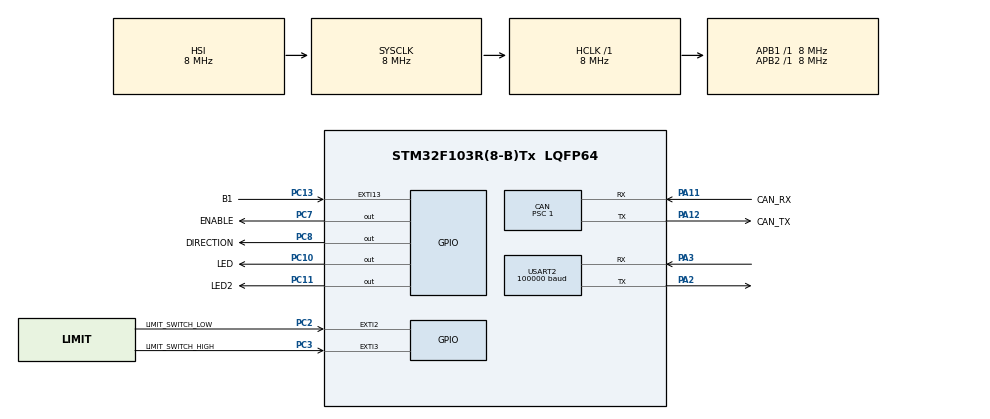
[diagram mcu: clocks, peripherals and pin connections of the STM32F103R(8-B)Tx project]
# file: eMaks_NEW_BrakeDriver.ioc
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CAN.BS1=CAN_BS1_4TQ
CAN.BS2=CAN_BS2_3TQ
CAN.CalculateTimeBit=1000
CAN.CalculateTimeQuantum=125.0
CAN.NART=ENABLE
CAN.Prescaler=1
Mcu.Family=STM32F1
Mcu.Name=STM32F103R(8-B)Tx
Mcu.Package=LQFP64
NVIC.CAN1_RX1_IRQn=true\:2\:0\:true\:false\:true\:true\:true
NVIC.EXTI15_10_IRQn=true\:0\:0\:false\:false\:true\:true\:true
NVIC.EXTI2_IRQn=true\:0\:0\:false\:false\:true\:true\:true
NVIC.EXTI3_IRQn=true\:0\:0\:false\:false\:true\:true\:true
NVIC.PriorityGroup=NVIC_PRIORITYGROUP_4
NVIC.TIM3_IRQn=true\:1\:0\:true\:false\:true\:true\:true
NVIC.USART2_IRQn=true\:0\:0\:false\:false\:true\:true\:true
NVIC.USB_HP_CAN1_TX_IRQn=true\:2\:0\:true\:false\:true\:true\:true
NVIC.USB_LP_CAN1_RX0_IRQn=true\:2\:0\:true\:false\:true\:true\:true
PA11.GPIO_Label=CAN_RX
PA11.Mode=Master
PA11.Signal=CAN_RX
PA12.GPIO_Label=CAN_TX
PA12.Mode=Master
PA12.Signal=CAN_TX
PA13.Mode=Serial_Wire
PA13.Signal=SYS_JTMS-SWDIO
PA14.Mode=Serial_Wire
PA14.Signal=SYS_JTCK-SWCLK
PA2.Mode=Asynchronous
PA2.Signal=USART2_TX
PA3.Mode=Asynchronous
PA3.Signal=USART2_RX
PC10.GPIO_Label=LED
PC10.Signal=GPIO_Output
PC11.GPIO_Label=LED2
PC11.Signal=GPIO_Output
PC13-TAMPER-RTC.GPIO_Label=B1
PC13-TAMPER-RTC.Signal=GPXTI13
PC2.GPIO_Label=LIMIT_SWITCH_LOW
PC2.GPIO_ModeDefaultEXTI=GPIO_MODE_IT_RISING_FALLING
PC2.Signal=GPXTI2
PC3.GPIO_Label=LIMIT_SWITCH_HIGH
PC3.GPIO_ModeDefaultEXTI=GPIO_MODE_IT_RISING_FALLING
PC3.Signal=GPXTI3
PC7.GPIO_Label=ENABLE
PC7.Signal=GPIO_Output
PC8.GPIO_Label=DIRECTION
PC8.Signal=GPIO_Output
ProjectManager.HeapSize=0x200
ProjectManager.StackSize=0x400
ProjectManager.TargetToolchain=TrueSTUDIO
RCC.AHBFreq_Value=8000000
RCC.APB1Freq_Value=8000000
RCC.APB1TimFreq_Value=8000000
RCC.APB2Freq_Value=8000000
RCC.APB2TimFreq_Value=8000000
RCC.HCLKFreq_Value=8000000
RCC.PLLMUL=RCC_PLL_MUL7
RCC.SYSCLKFreq_VALUE=8000000
RCC.USBFreq_Value=28000000
TIM2.Period=0xffff
TIM2.Prescaler=8
TIM3.AutoReloadPreload=TIM_AUTORELOAD_PRELOAD_ENABLE
TIM3.Period=1000
TIM3.Prescaler=800-1
USART2.BaudRate=100000
USART2.Parity=PARITY_EVEN
USART2.StopBits=STOPBITS_2
USART2.VirtualMode=VM_ASYNC
USART2.WordLength=WORDLENGTH_9B
VP_TIM2_VS_ClockSourceINT.Mode=Internal
VP_TIM3_VS_ClockSourceINT.Mode=Internal
board=custom

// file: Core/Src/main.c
/* USER CODE BEGIN Header */
/**
  ******************************************************************************
  * @file           : main.c
  * @brief          : Main program body
  ******************************************************************************
  * @attention
  *
  * <h2><center>&copy; Copyright (c) 2020 STMicroelectronics.
  * All rights reserved.</center></h2>
  *
  * This software component is licensed by ST under BSD 3-Clause license,
  * the "License"; You may not use this file except in compliance with the
  * License. You may obtain a copy of the License at:
  *                        opensource.org/licenses/BSD-3-Clause
  *
  ******************************************************************************
  */
/* USER CODE END Header */

#include "main.h"
#include "can.h"
#include "tim.h"
#include "usart.h"
#include "gpio.h"

void SystemClock_Config(void);

/* USER CODE BEGIN 0 */
//void HAL_GPIO_EXTI_Callback(uint16_t GPIO_Pin){
//	if(GPIO_Pin == B1_Pin){
//		static uint8_t data = 1;
//		if (data>100) data=1;
//		data++;
//		hal_can_send(&data);
//	}
//}
/* USER CODE END 0 */

int main(void)
{

  /* MCU Configuration--------------------------------------------------------*/

  /* Reset of all peripherals, Initializes the Flash interface and the Systick. */
  HAL_Init();

  /* Configure the system clock */
  SystemClock_Config();

  /* Initialize all configured peripherals */
  MX_GPIO_Init();
  MX_CAN_Init();
  MX_TIM3_Init();
  MX_TIM2_Init();
  MX_USART2_UART_Init();
  /* USER CODE BEGIN 2 */
  hal_can_filter_init();

  HAL_CAN_Start(&hcan);
  if (HAL_CAN_ActivateNotification(&hcan,CAN_IT_RX_FIFO0_MSG_PENDING) == HAL_OK){
	  HAL_GPIO_TogglePin(LED_GPIO_Port, LED_Pin);
  }

  /* USER CODE END 2 */

  /* Infinite loop */
  /* USER CODE BEGIN WHILE */
  while (1)
  {
//	 for(uint32_t i = 0; i <150000; i ++){
//		 if (i ==0){
//			 if(data>10) data =1;
//			 hal_can_send(data);
//			 data++;
//		 }
//	 }

    /* USER CODE END WHILE */

  }
}

void SystemClock_Config(void)
{
  RCC_OscInitTypeDef RCC_OscInitStruct = {0};
  RCC_ClkInitTypeDef RCC_ClkInitStruct = {0};

  /** Initializes the CPU, AHB and APB busses clocks
  */
  RCC_OscInitStruct.OscillatorType = RCC_OSCILLATORTYPE_HSI;
  RCC_OscInitStruct.HSIState = RCC_HSI_ON;
  RCC_OscInitStruct.HSICalibrationValue = RCC_HSICALIBRATION_DEFAULT;
  RCC_OscInitStruct.PLL.PLLState = RCC_PLL_NONE;
  if (HAL_RCC_OscConfig(&RCC_OscInitStruct) != HAL_OK)
  {
    Error_Handler();
  }
  /** Initializes the CPU, AHB and APB busses clocks
  */
  RCC_ClkInitStruct.ClockType = RCC_CLOCKTYPE_HCLK|RCC_CLOCKTYPE_SYSCLK
                              |RCC_CLOCKTYPE_PCLK1|RCC_CLOCKTYPE_PCLK2;
  RCC_ClkInitStruct.SYSCLKSource = RCC_SYSCLKSOURCE_HSI;
  RCC_ClkInitStruct.AHBCLKDivider = RCC_SYSCLK_DIV1;
  RCC_ClkInitStruct.APB1CLKDivider = RCC_HCLK_DIV1;
  RCC_ClkInitStruct.APB2CLKDivider = RCC_HCLK_DIV1;

  if (HAL_RCC_ClockConfig(&RCC_ClkInitStruct, FLASH_LATENCY_0) != HAL_OK)
  {
    Error_Handler();
  }
}

void Error_Handler(void)
{
}

/************************ (C) COPYRIGHT STMicroelectronics *****END OF FILE****/
